# H616 register map
Vendor: Allwinner; Series: H616; File version: 0.1
CPU: other 0, little endian, MPU, no FPU, 0 interrupt priority bits
Registers are 32-bit, read-write, reset 0x0 unless marked. A register's access mark holds for its fields unless they carry their own. Offsets are from the block's base; [hi:lo] are bit positions; {n}, {i} and the like mark numbered series; 'fields as' and 'values as' point back to an identical list.

## GPIO(PL)
Base 0x07022000
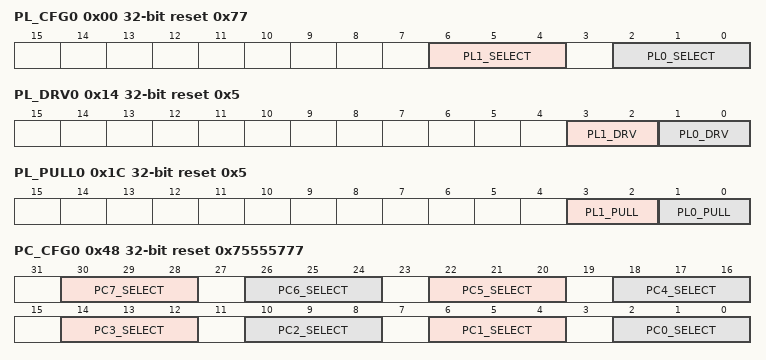
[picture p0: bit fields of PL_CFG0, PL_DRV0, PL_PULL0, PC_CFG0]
0x00 PL_CFG0 reset 0x77 — Port L Configure Register 0
  [6:4] PL1_SELECT — 000:Input 001:Output 010:Reserved 011:S_TWI0_SDA 100:Reserved 101:Reserved 110:Reserved 111:IO Disable
  [2:0] PL0_SELECT — 000:Input 001:Output 010:Reserved 011:S_TWI0_SCK 100:Reserved 101:Reserved 110:Reserved 111:IO Disable
0x10 PL_DAT — Port L Data Register
  [5:0] PL_DAT — If the port is configured as input, the corresponding bit is the pin state. If the port is configured as output, the pin state is the same as the corresponding bit. The read bit value is the value setup by software. If the port is configured as functional pin, the undefined value will be read.
0x14 PL_DRV0 reset 0x5 — Port L Multi-Driving Register 0
  [3:2] PL1_DRV — PL1 Multi-Driving Select 00: Level 0 01: Level 1 10: Level 2 11: Level 3
    {v}=Level_{v} (v=0..3)
  [1:0] PL0_DRV — PL0 Multi-Driving Select 00: Level 0 01: Level 1 10: Level 2 11: Level 3
    {v}=Level_{v} (v=0..3)
0x1C PL_PULL0 reset 0x5
  [3:2] PL1_PULL — PL1 Pull-up/down Select 00: Pull-up/down disable 01: Pull-up 10: Pull-down 11: Reserved
    0=Pull_minus_up_slash_down_disable (Pull-up/down disable); 1=Pull_minus_up (Pull-up); 2=Pull_minus_down (Pull-down)
  [1:0] PL0_PULL — PL0 Pull-up/down Select 00: Pull-up/down disable 01: Pull-up 10: Pull-down 11: Reserved
    values as PL1_PULL
0x48 PC_CFG0 reset 0x75555777
  [30:28] PC7_SELECT — 000:Input 001:Output 010:NAND_RB1 011:Reserved 100:SPI_CS1 101:Reserved 110:PC_EINT7 111:IO Disable
  [26:24] PC6_SELECT — 000:Input 001:Output 010:NAND_RB0 011:SDC2_CMD 100:Reserved 101:BOOT_SEL4 110:PC_EINT6 111:IO Disable
  [22:20] PC5_SELECT — 000:Input 001:Output 010:NAND_RE 011:SDC2_CLK 100:Reserved 100:BOOT_SEL3 110:PC_EINT5 111:IO Disable
  [18:16] PC4_SELECT — 000:Input 001:Output 010:NAND_CE0 011:Reserved 100:SPI_MISO 101:BOOT_SEL2 110:PC_EINT4 111:IO Disable
  [14:12] PC3_SELECT — 000:Input 001:Output 010:NAND_CE1 011:Reserved 100:SPI0_CS0 101:BOOT_SEL1 110:PC_EINT3 111:IO Disable
  [10:8] PC2_SELECT — 000:Input 001:Output 010:NAND_CLE 011:Reserved 100:SPI0_MOSI 101:Reserved 110:PC_EINT2 111:IO Disable
  [6:4] PC1_SELECT — 000:Input 001:Output 010:NAND_ALE 011:SDC2_RST 100:Reserved 101:Reserved 110:PC_EINT1 111:IO Disable
  [2:0] PC0_SELECT — 000:Input 001:Output 010:NAND_WE 011:SDC2_DS 100:SPI0_CLK 101:Reserved 110:PC_EINT0 111:IO Disable
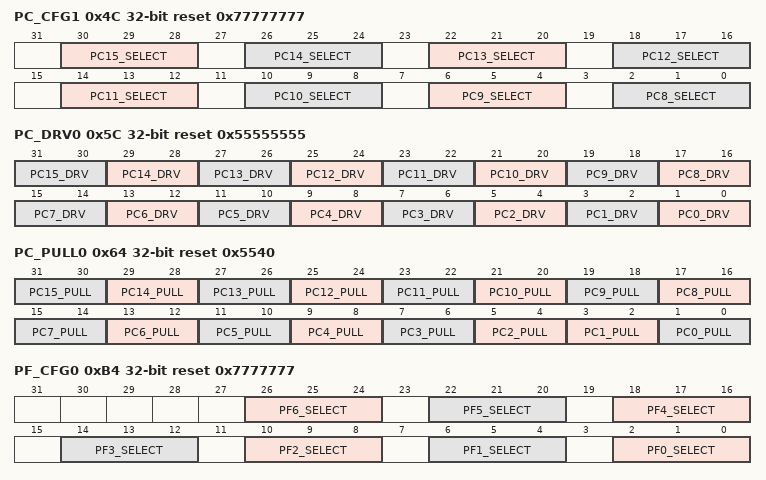
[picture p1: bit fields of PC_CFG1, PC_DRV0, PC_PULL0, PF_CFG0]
0x4C PC_CFG1 reset 0x77777777
  [30:28] PC15_SELECT — 000:Input 001:Output 010:NAND_DQ1 011:SDC2_D2 100:SPI0_WP 101:Reserved 110:PC_EINT15 111:IO Disable
  [26:24] PC14_SELECT — 000:Input 001:Output 010:NAND_DQ2 011:SDC2_D6 100:Reserved 101:Reserved 110:PC_EINT14 111:IO Disable
  [22:20] PC13_SELECT — 000:Input 001:Output 010:NAND_DQ3 011:SDC2_D1 100:Reserved 101:Reserved 110:PC_EINT13 111:IO Disable
  [18:16] PC12_SELECT — 000:Input 001:Output 010:NAND_DQS 011:Reserved 100:Reserved 101:Reserved 110:PC_EINT12 111:IO Disable
  [14:12] PC11_SELECT — 000:Input 001:Output 010:NAND_DQ4 011:SDC2_D5 100:Reserved 101:Reserved 110:PC_EINT11 111:IO Disable
  [10:8] PC10_SELECT — 000:Input 001:Output 010:NAND_DQ5 011:SDC2_D0 100:Reserved 101:Reserved 110:PC_EINT10 111:IO Disable
  [6:4] PC9_SELECT — 000:Input 001:Output 010:NAND_DQ6 011:SDC2_D4 100:Reserved 101:Reserved 110:PC_EINT9 111:IO Disable
  [2:0] PC8_SELECT — 000:Input 001:Output 010:NAND_DQ7 011:SDC2_D3 100:Reserved 101:Reserved 110:PC_EINT8 111:IO Disable
0x50 PC_CFG2 reset 0x7
  [2:0] PC16_SELECT — 000:Input 001:Output 010:NAND_DQ0 011:SDC2_D7 100:SPI0_HOLD 100:Reserved 110:PC_EINT16 111:IO Disable
0x58 PC_DAT
  [16:0] PC_DAT — If the port is configured as input, the corresponding bit is the pin state. If the port is configured as output, the pin state is the same as the corresponding bit. The read bit value is the value setup by software. If the port is configured as functional pin, the undefined value will be read.
0x5C PC_DRV0 reset 0x55555555
  [all] fields
    {v}=Level_{v} (v=0..3)
  [2n+1:2n] PC{n}_DRV (n=0..15) — PC{n} Multi-Driving Select 00: Level 0 01: Level 1 10: Level 2 11: Level 3
0x60 PC_DRV1 reset 0x1
  [1:0] PC16_DRV — PC16 Multi-Driving Select 00: Level 0 01: Level 1 10: Level 2 11: Level 3
    {v}=Level_{v} (v=0..3)
0x64 PC_PULL0 reset 0x5540
  [all] fields
    values as PL_PULL0.PL1_PULL
  [2n+1:2n] PC{n}_PULL (n=2..15) — PC{n} Pull-up/down Select 00: Pull-up/down disable 01: Pull-up 10: Pull-down 11: Reserved
  [3:2] PC1_PULL — PC Pull-up/down Select 00: Pull-up/down disable 01: Pull-up 10: Pull-down 11: Reserved
  [1:0] PC0_PULL — PC0 Pull-up/down Select 00: Pull-up/down disable 01: Pull-up 10: Pull-down 11: Reserved
0x68 PC_PULL1
  [1:0] PC16_PULL — PC16 Pull-up/down Select 00: Pull-up/down disable 01: Pull-up 10: Pull-down 11: Reserved
    values as PL_PULL0.PL1_PULL
0xB4 PF_CFG0 reset 0x7777777
  [26:24] PF6_SELECT — 000:Input 001:Output 010:Reserved 011:Reserved 100:Reserved 101:Reserved 110:PF_EINT6 111:IO Disable
  [22:20] PF5_SELECT — 000:Input 001:Output 010:SDC0_D2 011:JTAG_CK 100:Reserved 101:Reserved 110:PF_EINT5 111:IO Disable
  [18:16] PF4_SELECT — 000:Input 001:Output 010:SDC0_D3 011:UART0_RX 100:Reserved 101:Reserved 110:PF_EINT4 111:IO Disable
  [14:12] PF3_SELECT — 000:Input 001:Output 010:SDC0_CMD 011:JTAG_DO 100:Reserved 101:Reserved 110:PF_EINT3 111:IO Disable
  [10:8] PF2_SELECT — 000:Input 001:Output 010:SDC0_CLK 011:UART0_TX 100:Reserved 101:Reserved 110:PF_EINT2 111:IO Disable
  [6:4] PF1_SELECT — 000:Input 001:Output 010:SDC0_D0 011:JTAG_DI 100:Reserved 101:Reserved 110:PF_EINT1 111:IO Disable
  [2:0] PF0_SELECT — 000:Input 001:Output 010:SDC0_D1 011:JTAG_MS 100:Reserved 101:Reserved 110:PF_EINT0 111:IO Disable
0xC4 PF_DAT
  [6:0] PF_DAT — If the port is configured as input, the corresponding bit is the pin state. If the port is configured as output, the pin state is the same as the corresponding bit. The read bit value is the value setup by software. If the port is configured as functional pin, the undefined value will be read.
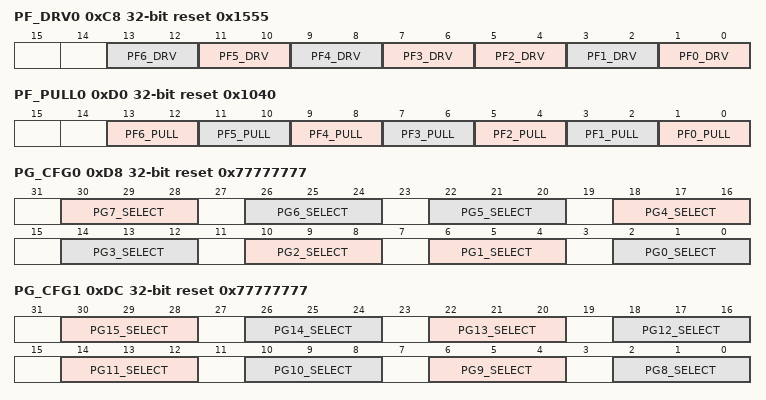
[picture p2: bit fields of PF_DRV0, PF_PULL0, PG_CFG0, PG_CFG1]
0xC8 PF_DRV0 reset 0x1555
  [2n+1:2n] PF{n}_DRV (n=3..6) — PF{n} Multi-Driving Select 00: Level 0 01: Level 1 10: Level 2 11: Level 3
    {v}=Level_{v} (v=0..3)
  [5:4] PF2_DRV — PF2 Multi-Driving Select 00: Level 0--180Ω 01: Level 1--120Ω 10: Level 2--100Ω 11: Level 3--50Ω
    0=Level_0_minus__minus_180Ω (Level 0--180Ω); 1=Level_1_minus__minus_120Ω (Level 1--120Ω); 2=Level_2_minus__minus_100Ω (Level 2--100Ω); 3=Level_3_minus__minus_50Ω (Level 3--50Ω)
  [3:2] PF1_DRV — PF1 Multi-Driving Select 00: Level 0 01: Level 1 10: Level 2 11: Level 3
    {v}=Level_{v} (v=0..3)
  [1:0] PF0_DRV — PF0 Multi-Driving Select 00: Level 0 01: Level 1 10: Level 2 11: Level 3
    {v}=Level_{v} (v=0..3)
0xD0 PF_PULL0 reset 0x1040
  [all] fields
    values as PL_PULL0.PL1_PULL
  [2n+1:2n] PF{n}_PULL (n=0..6) — PF{n} Pull-up/down Select 00: Pull-up/down disable 01: Pull-up 10: Pull-down 11: Reserved
0xD8 PG_CFG0 reset 0x77777777
  [30:28] PG7_SELECT — 000:Input 001:Output 010:UART1_RX 011:Reserved 100:JTAG_CK 101:Reserved 110:PG_EINT7 111:IO Disable
  [26:24] PG6_SELECT — 000:Input 001:Output 010:UART1_TX 011:Reserved 100:JTAG_MS 101:Reserved 110:PG_EINT6 111:IO Disable
  [4n+2:4n] PG{n}_SELECT (n=2..5) — 000:Input 001:Output 010:SDC1_D{n-2} 011:Reserved 100:Reserved 101:Reserved 110:PG_EINT{n} 111:IO Disable
  [6:4] PG1_SELECT — 000:Input 001:Output 010:SDC1_CMD 011:Reserved 100:Reserved 101:Reserved 110:PG_EINT1 111:IO Disable
  [2:0] PG0_SELECT — 000:Input 001:Output 010:SDC1_CLK 011:Reserved 100:Reserved 101:Reserved 110:PG_EINT0 111:IO Disable
0xDC PG_CFG1 reset 0x77777777
  [30:28] PG15_SELECT — 000:Input 001:Output 010:UART2_TX 011:Reserved 100:Reserved 101:TWI4_SCK 110:PG_EINT15 111:IO Disable
  [26:24] PG14_SELECT — 000:Input 001:Output 010:H_I2S2_DIN0 011:H_I2S2_DOUT1 100:BIST_RESULT3 101:Reserved 110:PG_EINT14 111:IO Disable
  [22:20] PG13_SELECT — 000:Input 001:Output 010:H_I2S2_DOUT0 011:H_I2S2_DIN1 100:BIST_RESULT2 101:Reserved 110:PG_EINT13 111:IO Disable
  [18:16] PG12_SELECT — 000:Input 001:Output 010:H_I2S2_LRCK 011:Reserved 100:BIST_RESULT1 101:Reserved 110:PG_EINT12 111:IO Disable
  [14:12] PG11_SELECT — 000:Input 001:Output 010:H_I2S2_BCLK 011:Reserved 100:BIST_RESULT0 101:Reserved 110:PG_EINT11 111:IO Disable
  [10:8] PG10_SELECT — 000:Input 001:Output 010:H_I2S2_MCLK 011:X32KFOUT 100:Reserved 101:Reserved 110:PG_EINT10 111:IO Disable
  [6:4] PG9_SELECT — 000:Input 001:Output 010:UART1_CTS 011:Reserved 100:JTAG_DI 101:Reserved 110:PG_EINT9 111:IO Disable
  [2:0] PG8_SELECT — 000:Input 001:Output 010:UART1_RTS 011:PLL_LOCK_DBG 100:JTAG_DO 101:Reserved 110:PG_EINT8 111:IO Disable
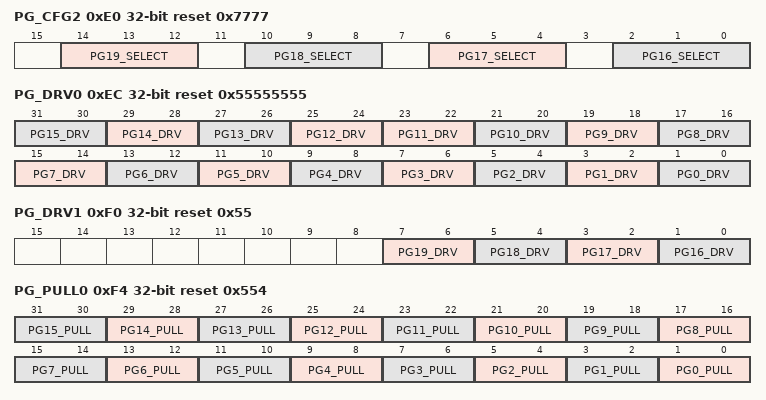
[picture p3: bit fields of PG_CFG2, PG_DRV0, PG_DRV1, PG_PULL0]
0xE0 PG_CFG2 reset 0x7777
  [14:12] PG19_SELECT — 000:Input 001:Output 010:Reserved 011:Reserved 100:PWM1 101:Reserved 110:PG_EINT19 111:IO Disable
  [10:8] PG18_SELECT — 000:Input 001:Output 010:UART2_CTS 011:Reserved 100:Reserved 101:TWI3_SDA 110:PG_EINT18 111:IO Disable
  [6:4] PG17_SELECT — 000:Input 001:Output 010:UART2_RTS 011:Reserved 100:Reserved 101:TWI3_SCK 110:PG_EINT17 111:IO Disable
  [2:0] PG16_SELECT — 000:Input 001:Output 010:UART2_RX 011:Reserved 100:Reserved 101:TWI4_SDA 110:PG_EINT16 111:IO Disable
0xE8 PG_DAT
  [19:0] PG_DAT — If the port is configured as input, the corresponding bit is the pin state. If the port is configured as output, the pin state is the same as the corresponding bit. The read bit value is the value setup by software. If the port is configured as functional pin, the undefined value will be read.
0xEC PG_DRV0 reset 0x55555555
  [2n+1:2n] PG{n}_DRV (n=12..15) — PG{n} Multi-Driving Select 00: Level 0 01: Level 1 10: Level 2 11: Level 3
    {v}=Level_{v} (v=0..3)
  [23:22] PG11_DRV — PG11 Multi-Driving Select 00: Level 0--180Ω 01: Level 1--120Ω 10: Level 2--100Ω 11: Level 3--50Ω
    values as PF_DRV0.PF2_DRV
  [21:20] PG10_DRV — PG10 Multi-Driving Select 00: Level 0--180Ω 01: Level 1--120Ω 10: Level 2--100Ω 11: Level 3--50Ω
    values as PF_DRV0.PF2_DRV
  [2n+1:2n] PG{n}_DRV (n=1..9) — PG{n} Multi-Driving Select 00: Level 0 01: Level 1 10: Level 2 11: Level 3
    {v}=Level_{v} (v=0..3)
  [1:0] PG0_DRV — PG0 Multi-Driving Select 00: Level 0--180Ω 01: Level 1--120Ω 10: Level 2--100Ω 11: Level 3--50Ω
    values as PF_DRV0.PF2_DRV
0xF0 PG_DRV1 reset 0x55
  [7:6] PG19_DRV — PG19 Multi-Driving Select 00: Level 0--180Ω 01: Level 1--120Ω 10: Level 2--100Ω 11: Level 3--50Ω
    values as PF_DRV0.PF2_DRV
  [5:4] PG18_DRV — PG18 Multi-Driving Select 00: Level 0 01: Level 1 10: Level 2 11: Level 3
    {v}=Level_{v} (v=0..3)
  [3:2] PG17_DRV — PG17 Multi-Driving Select 00: Level 0 01: Level 1 10: Level 2 11: Level 3
    {v}=Level_{v} (v=0..3)
  [1:0] PG16_DRV — PG16 Multi-Driving Select 00: Level 0 01: Level 1 10: Level 2 11: Level 3
    {v}=Level_{v} (v=0..3)
0xF4 PG_PULL0 reset 0x554
  [all] fields
    values as PL_PULL0.PL1_PULL
  [2n+1:2n] PG{n}_PULL (n=0..15) — PG{n} Pull-up/down Select 00: Pull-up/down disable 01: Pull-up 10: Pull-down 11: Reserved
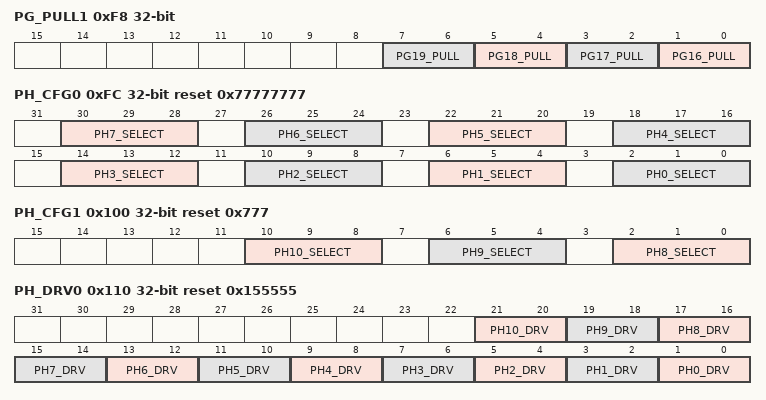
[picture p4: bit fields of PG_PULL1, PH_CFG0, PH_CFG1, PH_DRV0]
0xF8 PG_PULL1
  [all] fields
    values as PL_PULL0.PL1_PULL
  [2n-31:2n-32] PG{n}_PULL (n=16..19) — PG{n} Pull-up/down Select 00: Pull-up/down disable 01: Pull-up 10: Pull-down 11: Reserved
0xFC PH_CFG0 reset 0x77777777
  [30:28] PH7_SELECT — 000:Input 001:Output 010:UART2_RTS 011:H_I2S3_LRCK 100:SPI1_MOSI 100:TWI4_SDA 110:PH_EINT7 111:IO Disable
  [26:24] PH6_SELECT — 000:Input 001:Output 010:UART2_RX 011:H_I2S3_BCLK 100:SPI1_CLK 100:TWI4_SCK 110:PH_EINT6 111:IO Disable
  [22:20] PH5_SELECT — 000:Input 001:Output 010:UART2_TX 011:H_I2S3_MCLK 100:SPI1_CS0 100:TWI3_SDA 110:PH_EINT5 111:IO Disable
  [18:16] PH4_SELECT — 000:Input 001:Output 010:Reserved 011:OWA_OUT 100:Reserved 100:TWI3_SCK 110:PH_EINT4 111:IO Disable
  [14:12] PH3_SELECT — 000:Input 001:Output 010:UART5_RX 011:Reserved 100:PWM1 100:TWI2_SDA 110:PH_EINT3 111:IO Disable
  [10:8] PH2_SELECT — 000:Input 001:Output 010:UART5_TX 011:OWA_MCLK 100:PWM2 100:TWI2_SCK 110:PH_EINT2 111:IO Disable
  [6:4] PH1_SELECT — 000:Input 001:Output 010:UART0_RX 011:Reserved 100:PWM4 100:TWI1_SDA 110:PH_EINT1 111:IO Disable
  [2:0] PH0_SELECT — 000:Input 001:Output 010:UART0_TX 011:Reserved 100:PWM3 100:TWI1_SCK 110:PH_EINT0 111:IO Disable
0x100 PH_CFG1 reset 0x777
  [10:8] PH10_SELECT — 000:Input 001:Output 010:Reserved 011:IR_RX 100:TCON_TRIG1 100:Reserved 110:PH_EINT10 111:IO Disable
  [6:4] PH9_SELECT — 000:Input 001:Output 010:Reserved 011:H_I2S3_DIN0 100:SPI1_CS1 100:H_I2S3_DOUT1 110:PH_EINT9 111:IO Disable
  [2:0] PH8_SELECT — 000:Input 001:Output 010:UART2_CTS 011:H_I2S3_DOUT0 100:SPI1_MISO 100:H_I2S3_DIN1 110:PH_EINT8 111:IO Disable
0x10C PH_DAT
  [10:0] PH_DAT — If the port is configured as input, the corresponding bit is the pin state. If the port is configured as output, the pin state is the same as the corresponding bit. The read bit value is the value setup by software. If the port is configured as functional pin, the undefined value will be read.
0x110 PH_DRV0 reset 0x155555
  [all] fields
    {v}=Level_{v} (v=0..3)
  [2n+1:2n] PH{n}_DRV (n=0..10) — PH{n} Multi-Driving Select 00: Level 0 01: Level 1 10: Level 2 11: Level 3
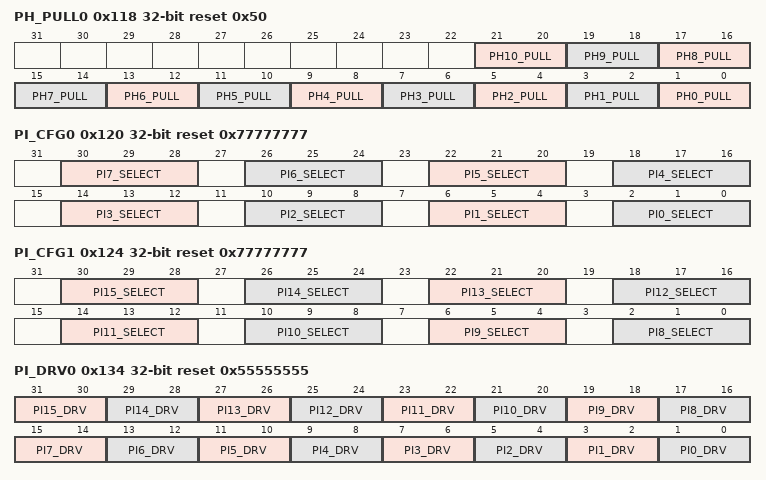
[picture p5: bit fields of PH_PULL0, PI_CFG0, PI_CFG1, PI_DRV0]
0x118 PH_PULL0 reset 0x50
  [all] fields
    values as PL_PULL0.PL1_PULL
  [2n+1:2n] PH{n}_PULL (n=0..10) — PH{n} Pull-up/down Select 00: Pull-up/down disable 01: Pull-up 10: Pull-down 11: Reserved
0x120 PI_CFG0 reset 0x77777777
  [30:28] PI7_SELECT — 000:Input 001:Output 010:RGMII_TXD3/RMII_NULL 011:UART2_RTS 100:TS0_SYNC 101:TWI1_SCK 110:PI_EINT7 111:IO Disable
  [26:24] PI6_SELECT — 000:Input 001:Output 010:RGMII_NULL/RMII_RXER 011:UART2_RX 100:TS0_ERR 101:TWI0_SDA 110:PI_EINT6 111:IO Disable
  [22:20] PI5_SELECT — 000:Input 001:Output 010:RGMII_RXCTL/RMII_CRS_DV 011:UART2_TX 100:TS0_CLK 101:TWI0_SCK 110:PI_EINT5 111:IO Disable
  [18:16] PI4_SELECT — 000:Input 001:Output 010:RGMII_RXCK/RMII_NULL 011:DMIC_DATA3 100:H_I2S0_DIN0 101:H_I2S0_DOUT1 110:PI_EINT4 111:IO Disable
  [14:12] PI3_SELECT — 000:Input 001:Output 010:RGMII_RXD0/RMII_RXD0 011:DMIC_DATA2 100:H_I2S0_DOUT0 101:H_I2S0_DIN1 110:PI_EINT3 111:IO Disable
  [10:8] PI2_SELECT — 000:Input 001:Output 010:RGMII_RXD1/RMII_RXD1 011:DMIC_DATA1 100:H_I2S0_LRCK 101:HDMI_CEC 110:PI_EINT2 111:IO Disable
  [6:4] PI1_SELECT — 000:Input 001:Output 010:RGMII_RXD2/RMII_NULL 011:DMIC_DATA0 100:H_I2S0_BCLK 101:HDMI_SDA 110:PI_EINT1 111:IO Disable
  [2:0] PI0_SELECT — 000:Input 001:Output 010:RGMII_RXD3/RMII_NULL 011:DMIC_CLK 100:H_I2S0_MCLK 101:HDMI_SCL 110:PI_EINT0 111:IO Disable
0x124 PI_CFG1 reset 0x77777777
  [30:28] PI15_SELECT — 000:Input 001:Output 010:MDIO 011:UART4_RTS 100:TS0_D6 101:CLK_FANOUT0 110:PI_EINT15 111:IO Disable
  [26:24] PI14_SELECT — 000:Input 001:Output 010:MDC 011:UART4_RX 100:TS0_D5 101:PWM4 110:PI_EINT14 111:IO Disable
  [22:20] PI13_SELECT — 000:Input 001:Output 010:RGMII_CLKIN/RMII_NULL 011:UART4_TX 100:TS0_D4 101:PWM3 110:PI_EINT13 111:IO Disable
  [18:16] PI12_SELECT — 000:Input 001:Output 010:RGMII_TXCTL/RMII_TXEN 011:UART3_CTS 100:TS0_D3 101:PWM2 110:PI_EINT12 111:IO Disable
  [14:12] PI11_SELECT — 000:Input 001:Output 010:RGMII_TXCK/RMII_TXCK 011:UART3_RTS 100:TS0_D2 101:PWM1 110:PI_EINT11 111:IO Disable
  [10:8] PI10_SELECT — 000:Input 001:Output 010:RGMII_TXD0/RMII_TXD0 011:UART3_RX 100:TS0_D1 101:TWI2_SDA 110:PI_EINT10 111:IO Disable
  [6:4] PI9_SELECT — 000:Input 001:Output 010:RGMII_TXD1/RMII_TXD1 011:UART3_TX 100:TS0_D0 101:TWI2_SCK 110:PI_EINT9 111:IO Disable
  [2:0] PI8_SELECT — 000:Input 001:Output 010:RGMII_TXD2/RMII_NULL 011:UART2_RTS 100:TS0_DVLD 101:TWI1_SDA 110:PI_EINT8 111:IO Disable
0x128 PI_CFG2 reset 0x7
  [2:0] PI16_SELECT — 000:Input 001:Output 010:EPHY_25M 011:UART4_CTS 100:TS0_D7 101:CLK_FANOUT1 110:PI_EINT16 111:IO Disable
0x130 PI_DAT
  [16:0] PI_DAT — If the port is configured as input, the corresponding bit is the pin state. If the port is configured as output, the pin state is the same as the corresponding bit. The read bit value is the value setup by software. If the port is configured as functional pin, the undefined value will be read.
0x134 PI_DRV0 reset 0x55555555
  [31:30] PI15_DRV — PI15 Multi-Driving Select 00: Level 0--180Ω 01: Level 1--120Ω 10: Level 2--100Ω 11: Level 3--50Ω
    values as PF_DRV0.PF2_DRV
  [29:28] PI14_DRV — PI14 Multi-Driving Select 00: Level 0 01: Level 1 10: Level 2 11: Level 3
    {v}=Level_{v} (v=0..3)
  [27:26] PI13_DRV — PI13 Multi-Driving Select 00: Level 0 01: Level 1 10: Level 2 11: Level 3
    {v}=Level_{v} (v=0..3)
  [25:24] PI12_DRV — PI12 Multi-Driving Select 00: Level 0 01: Level 1 10: Level 2 11: Level 3
    {v}=Level_{v} (v=0..3)
  [23:22] PI11_DRV — PI11 Multi-Driving Select 00: Level 0--180Ω 01: Level 1--120Ω 10: Level 2--100Ω 11: Level 3--50Ω
    values as PF_DRV0.PF2_DRV
  [2n+1:2n] PI{n}_DRV (n=0..10) — PI{n} Multi-Driving Select 00: Level 0 01: Level 1 10: Level 2 11: Level 3
    {v}=Level_{v} (v=0..3)
0x138 PI_DRV1 reset 0x1
  [1:0] PI16_DRV — PI16 Multi-Driving Select 00: Level 0--180Ω 01: Level 1--120Ω 10: Level 2--100Ω 11: Level 3--50Ω
    values as PF_DRV0.PF2_DRV
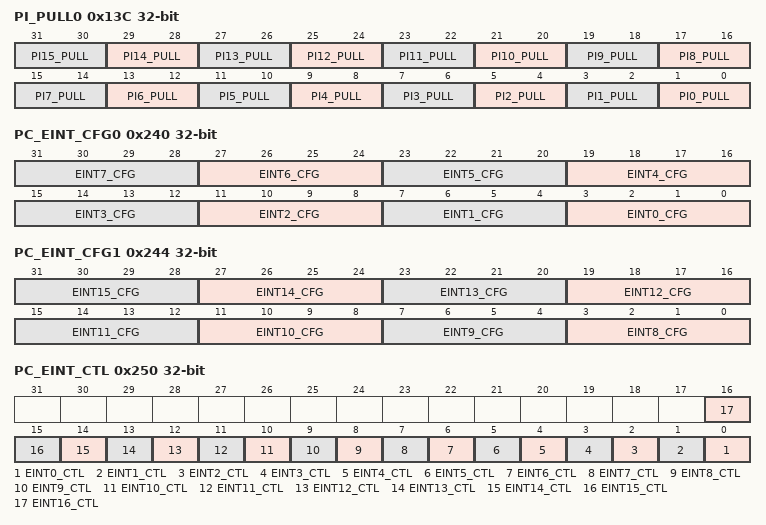
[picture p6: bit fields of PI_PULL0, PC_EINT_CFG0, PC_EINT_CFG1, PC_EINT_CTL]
0x13C PI_PULL0
  [all] fields
    values as PL_PULL0.PL1_PULL
  [2n+1:2n] PI{n}_PULL (n=0..15) — PI{n} Pull-up/down Select 00: Pull-up/down disable 01: Pull-up 10: Pull-down 11: Reserved
0x140 PI_PULL1
  [1:0] PI16_PULL — PI16 Pull-up/down Select 00: Pull-up/down disable 01: Pull-up 10: Pull-down 11: Reserved
    values as PL_PULL0.PL1_PULL
0x240 PC_EINT_CFG0
  [all] fields
    0=Positive_Edge; 1=Negative_Edge; 2=High_Level; 3=Low_Level; 4=Double Edge (Positive/ Negative) Others: Reserved
  [4n+3:4n] EINT{n}_CFG (n=0..7) — External INT{n} Mode 0x0: Positive Edge 0x1: Negative Edge 0x2: High Level 0x3: Low Level 0x4: Double Edge (Positive/ Negative) Others: Reserved
0x244 PC_EINT_CFG1
  [all] fields
    values as the fields of PC_EINT_CFG0
  [4n-29:4n-32] EINT{n}_CFG (n=8..15) — External INT{n} Mode 0x0: Positive Edge 0x1: Negative Edge 0x2: High Level 0x3: Low Level 0x4: Double Edge (Positive/ Negative) Others: Reserved
0x248 PC_EINT_CFG2
  [3:0] EINT16_CFG — External INT16 Mode 0x0: Positive Edge 0x1: Negative Edge 0x2: High Level 0x3: Low Level 0x4: Double Edge (Positive/ Negative) Others: Reserved
    values as the fields of PC_EINT_CFG0
0x250 PC_EINT_CTL
  [all] fields
    0=Disable; 1=Enable
  [n] EINT{n}_CTL (n=0..16) — External INT{n} Enable 0: Disable 1: Enable
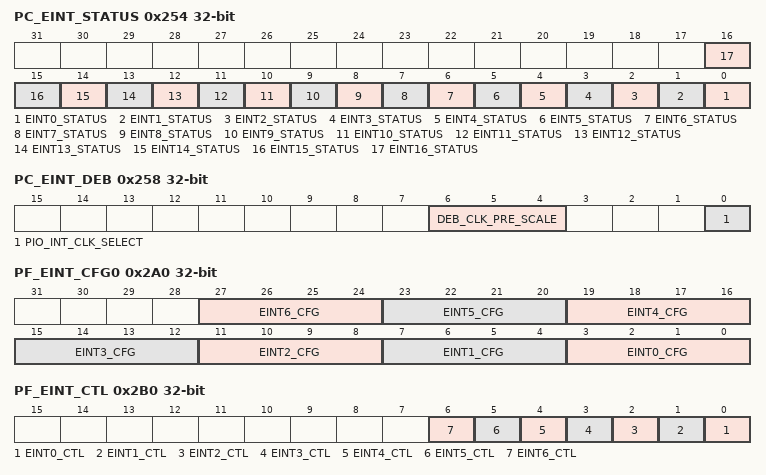
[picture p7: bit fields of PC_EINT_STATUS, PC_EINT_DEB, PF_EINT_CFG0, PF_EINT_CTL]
0x254 PC_EINT_STATUS
  [all] fields
    0=No IRQ pending; 1=IRQ pending Write `1` to clear
  [n] EINT{n}_STATUS (n=0..16) — External INT{n} Pending Bit 0: No IRQ pending 1: IRQ pending Write `1` to clear
0x258 PC_EINT_DEB
  [6:4] DEB_CLK_PRE_SCALE — Debounce Clock Pre-scale n The selected clock source is prescaled by 2^n.
  [0] PIO_INT_CLK_SELECT — PIO Interrupt Clock Select 0: LOSC 32KHz 1: HOSC 24MHz
    0=LOSC (LOSC 32KHz); 1=HOSC (HOSC 24MHz)
0x2A0 PF_EINT_CFG0
  [all] fields
    values as the fields of PC_EINT_CFG0
  [4n+3:4n] EINT{n}_CFG (n=0..6) — External INT{n} Mode 0x0: Positive Edge 0x1: Negative Edge 0x2: High Level 0x3: Low Level 0x4: Double Edge (Positive/ Negative) Others: Reserved
0x2B0 PF_EINT_CTL
  [all] fields
    0=Disable; 1=Enable
  [n] EINT{n}_CTL (n=0..6) — External INT{n} Enable 0: Disable 1: Enable
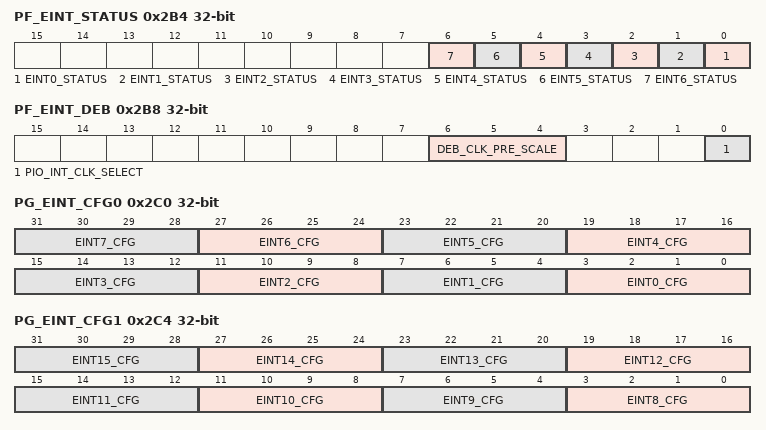
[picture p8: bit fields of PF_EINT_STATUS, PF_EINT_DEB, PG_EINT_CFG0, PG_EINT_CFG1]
0x2B4 PF_EINT_STATUS
  [all] fields
    0=No IRQ pending; 1=IRQ pending Write `1` to clear
  [n] EINT{n}_STATUS (n=0..6) — External INT{n} Pending Bit 0: No IRQ pending 1: IRQ pending Write `1` to clear
0x2B8 PF_EINT_DEB
  fields as PC_EINT_DEB
0x2C0 PG_EINT_CFG0
  fields as PC_EINT_CFG0
0x2C4 PG_EINT_CFG1
  fields as PC_EINT_CFG1
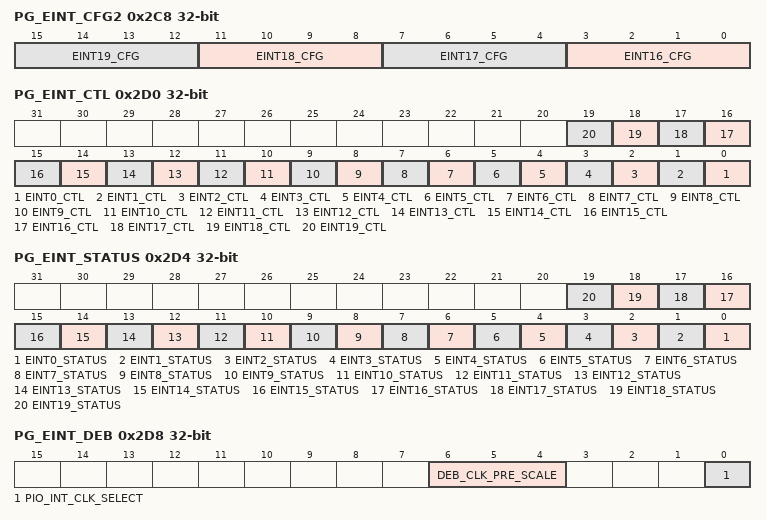
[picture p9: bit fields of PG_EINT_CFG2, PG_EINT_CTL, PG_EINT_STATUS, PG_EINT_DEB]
0x2C8 PG_EINT_CFG2
  [all] fields
    values as the fields of PC_EINT_CFG0
  [4n-61:4n-64] EINT{n}_CFG (n=16..19) — External INT{n} Mode 0x0: Positive Edge 0x1: Negative Edge 0x2: High Level 0x3: Low Level 0x4: Double Edge (Positive/ Negative) Others: Reserved
0x2D0 PG_EINT_CTL
  [all] fields
    0=Disable; 1=Enable
  [n] EINT{n}_CTL (n=0..19) — External INT{n} Enable 0: Disable 1: Enable
0x2D4 PG_EINT_STATUS
  [all] fields
    0=No IRQ pending; 1=IRQ pending Write `1` to clear
  [n] EINT{n}_STATUS (n=0..19) — External INT{n} Pending Bit 0: No IRQ pending 1: IRQ pending Write `1` to clear
0x2D8 PG_EINT_DEB
  fields as PC_EINT_DEB
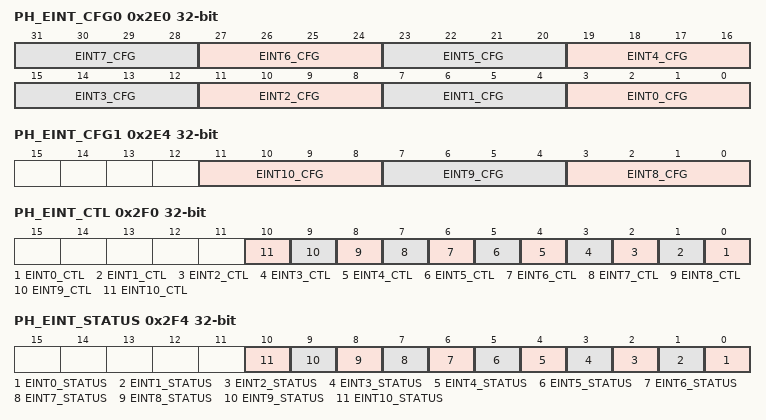
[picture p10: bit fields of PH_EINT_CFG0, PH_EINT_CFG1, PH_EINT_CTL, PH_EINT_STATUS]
0x2E0 PH_EINT_CFG0
  fields as PC_EINT_CFG0
0x2E4 PH_EINT_CFG1
  [all] fields
    values as the fields of PC_EINT_CFG0
  [11:8] EINT10_CFG — External INT10 Mode 0x0: Positive Edge 0x1: Negative Edge 0x2: High Level 0x3: Low Level 0x4: Double Edge (Positive/ Negative) Others: Reserved
  [7:4] EINT9_CFG — External INT9 Mode 0x0: Positive Edge 0x1: Negative Edge 0x2: High Level 0x3: Low Level 0x4: Double Edge (Positive/ Negative) Others: Reserved
  [3:0] EINT8_CFG — External INT8 Mode 0x0: Positive Edge 0x1: Negative Edge 0x2: High Level 0x3: Low Level 0x4: Double Edge (Positive/ Negative) Others: Reserved
0x2F0 PH_EINT_CTL
  [all] fields
    0=Disable; 1=Enable
  [n] EINT{n}_CTL (n=0..10) — External INT{n} Enable 0: Disable 1: Enable
0x2F4 PH_EINT_STATUS
  [all] fields
    0=No IRQ pending; 1=IRQ pending Write `1` to clear
  [n] EINT{n}_STATUS (n=0..10) — External INT{n} Pending Bit 0: No IRQ pending 1: IRQ pending Write `1` to clear
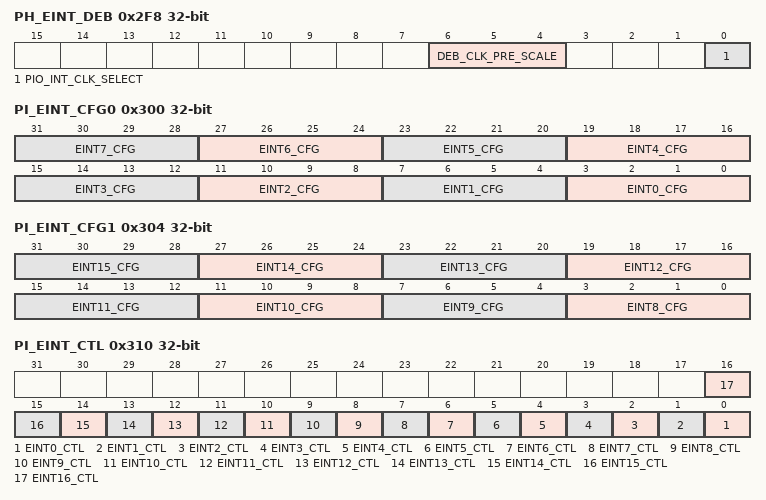
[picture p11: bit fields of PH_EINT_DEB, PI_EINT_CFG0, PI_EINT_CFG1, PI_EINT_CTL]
0x2F8 PH_EINT_DEB
  fields as PC_EINT_DEB
0x300 PI_EINT_CFG0
  fields as PC_EINT_CFG0
0x304 PI_EINT_CFG1
  fields as PC_EINT_CFG1
0x308 PI_EINT_CFG2
  fields as PC_EINT_CFG2
0x310 PI_EINT_CTL
  fields as PC_EINT_CTL
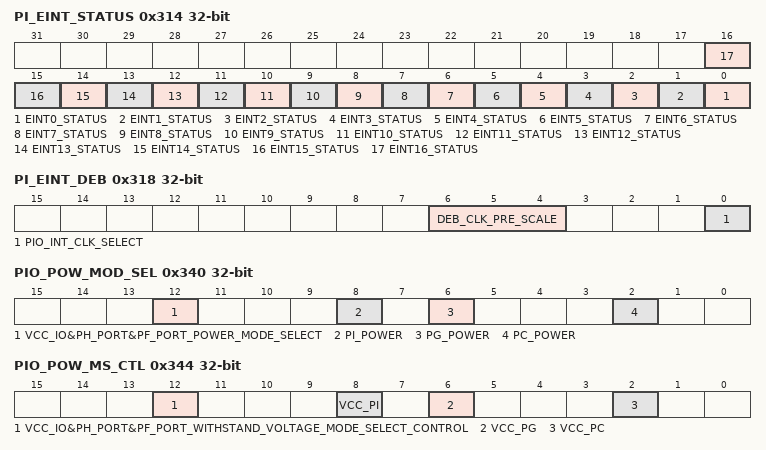
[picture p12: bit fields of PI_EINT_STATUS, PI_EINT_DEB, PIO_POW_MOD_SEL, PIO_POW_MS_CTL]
0x314 PI_EINT_STATUS
  fields as PC_EINT_STATUS
0x318 PI_EINT_DEB
  fields as PC_EINT_DEB
0x340 PIO_POW_MOD_SEL
  [all] fields
    0=_3_point_3_V (3.3 V); 1=_1_point_8_V (1.8 V)
  [12] VCC_IO&PH_PORT&PF_PORT_POWER_MODE_SELECT — VCC-IO&PH_Port&PF_Port POWER MODE Select 0: 3.3 V 1: 1.8 V
  [8] PI_POWER — MODE Select 0: 3.3 V 1: 1.8 V
  [6] PG_POWER — MODE Select 0: 3.3 V 1: 1.8 V
  [2] PC_POWER — MODE Select 0: 3.3 V 1: 1.8 V
0x344 PIO_POW_MS_CTL
  [all] fields
    0=Enable; 1=Disable
  [12] VCC_IO&PH_PORT&PF_PORT_WITHSTAND_VOLTAGE_MODE_SELECT_CONTROL — VCC-IO&PH_Port&PF_Port Withstand Voltage Mode Select Control 0: Enable 1: Disable
  [8] VCC_PI — Withstand Voltage Mode Select Control 0: Enable 1: Disable
  [6] VCC_PG — Withstand Voltage Mode Select Control 0: Enable 1: Disable
  [2] VCC_PC — Withstand Voltage Mode Select Control 0: Enable 1: Disable
0x350 PIO_PV_SEL_CTL reset 0x1
  [0] PF — Port Power Voltage Select Control 0: 1.8 V 1: 3.3 V
    0=_1_point_8_V (1.8 V); 1=_3_point_3_V (3.3 V)
